# V3s register map
Vendor: Allwinner; Series: V3s; File version: 0.1
CPU: ARM Cortex-A7 MP1 0, little endian, MPU, no FPU, 0 interrupt priority bits
Registers are 32-bit, read-write, reset 0x0 unless marked. A register's access mark holds for its fields unless they carry their own. Offsets are from the block's base; [hi:lo] are bit positions; {n}, {i} and the like mark numbered series; 'fields as' and 'values as' point back to an identical list.

## PIO
Base 0x01C20800
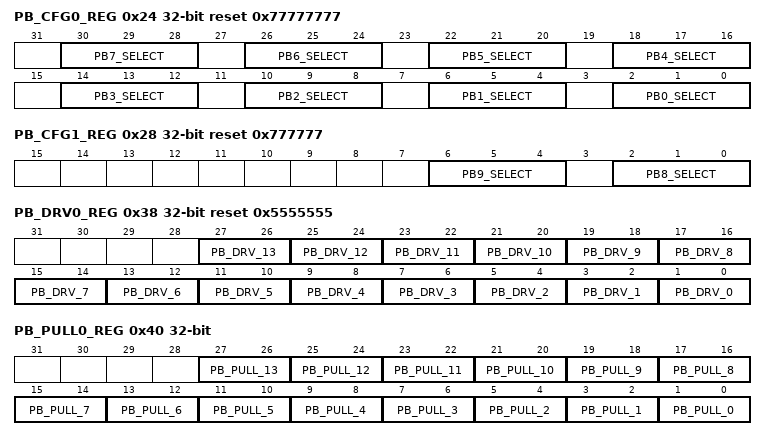
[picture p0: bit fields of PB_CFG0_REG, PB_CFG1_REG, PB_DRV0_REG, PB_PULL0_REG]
0x24 PB_CFG0_REG reset 0x77777777
  [30:28] PB7_SELECT — 000: Input 001: Output 010: TWI0_SDA 011: Reserved 100: Reserved 101: Reserved 110: PB_EINT7 111: IO Disable
    0=Input; 1=Output; 2=TWI0_SDA; 6=PB_EINT7; 7=IO (IO Disable)
  [26:24] PB6_SELECT — 000: Input 001: Output 010: TWI0_SCK 011: Reserved 100: Reserved 101: Reserved 110: PB_EINT6 111: IO Disable
    0=Input; 1=Output; 2=TWI0_SCK; 6=PB_EINT6; 7=IO (IO Disable)
  [22:20] PB5_SELECT — 000: Input 001: Output 010: PWM1 011: Reserved 100: Reserved 101: Reserved 110: PB_EINT5 111: IO Disable
    0=Input; 1=Output; 2=PWM1; 6=PB_EINT5; 7=IO (IO Disable)
  [18:16] PB4_SELECT — 000: Input 001: Output 010: PWM0 011: Reserved 100: Reserved 101: Reserved 110: PB_EINT4 111: IO Disable
    0=Input; 1=Output; 2=PWM0; 6=PB_EINT4; 7=IO (IO Disable)
  [14:12] PB3_SELECT — 000: Input 001: Output 010: UART2_CTS 011: Reserved 100: Reserved 101: Reserved 110: PB_EINT3 111: IO Disable
    0=Input; 1=Output; 2=UART2_CTS; 6=PB_EINT3; 7=IO (IO Disable)
  [10:8] PB2_SELECT — 000: Input 001: Output 010: UART2_RTS 011: Reserved 100: Reserved 101: Reserved 110: PB_EINT2 111: IO Disable
    0=Input; 1=Output; 2=UART2_RTS; 6=PB_EINT2; 7=IO (IO Disable)
  [6:4] PB1_SELECT — 000: Input 001: Output 010: UART2_RX 011: Reserved 100: Reserved 101: Reserved 110: PB_EINT1 111: IO Disable
    0=Input; 1=Output; 2=UART2_RX; 6=PB_EINT1; 7=IO (IO Disable)
  [2:0] PB0_SELECT — 000: Input 001: Output 010: UART2_TX 011: Reserved 100: Reserved 101: Reserved 110: PB_EINT0 111: IO Disable
    0=Input; 1=Output; 2=UART2_TX; 6=PB_EINT0; 7=IO (IO Disable)
0x28 PB_CFG1_REG reset 0x777777
  [6:4] PB9_SELECT — 000: Input 001: Output 010: TWI1_SDA 011: UART0_RX 100: Reserved 101: Reserved 110: PB_EINT9 111: IO Disable
    0=Input; 1=Output; 2=TWI1_SDA; 3=UART0_RX; 6=PB_EINT9; 7=IO (IO Disable)
  [2:0] PB8_SELECT — 000: Input 001: Output 010: TWI1_SCK 011: UART0_TX 100: Reserved 101: Reserved 110: PB_EINT8 111: IO Disable
    0=Input; 1=Output; 2=TWI1_SCK; 3=UART0_TX; 6=PB_EINT8; 7=IO (IO Disable)
0x2C PB_CFG2_REG reset not defined
0x30 PB_CFG3_REG reset not defined
0x34 PB_DATA_REG
  [13:0] PB_DAT — If the port is configured as input, the corresponding bit is the pin state. If the port is configured as output, the pin state is the same as the corresponding bit. The read bit value is the value setup by software. If the port is configured as functional pin, the undefined value will be read.
0x38 PB_DRV0_REG reset 0x5555555
  [2n+1:2n] PB_DRV_{n} (n=0..13) — PB[n] Multi-Driving Select (n = 0~13) 00: Level 0 01: Level 1 10: Level 2 11: Level 3
0x3C PB_DRV1_REG reset not defined
0x40 PB_PULL0_REG
  [2n+1:2n] PB_PULL_{n} (n=0..13) — PB[n] Pull-up/down Select (n = 0~13)00: Pull-up/down disable01: Pull-up 10: Pull-down 11: Reserved
0x44 PB_PULL1_REG reset not defined
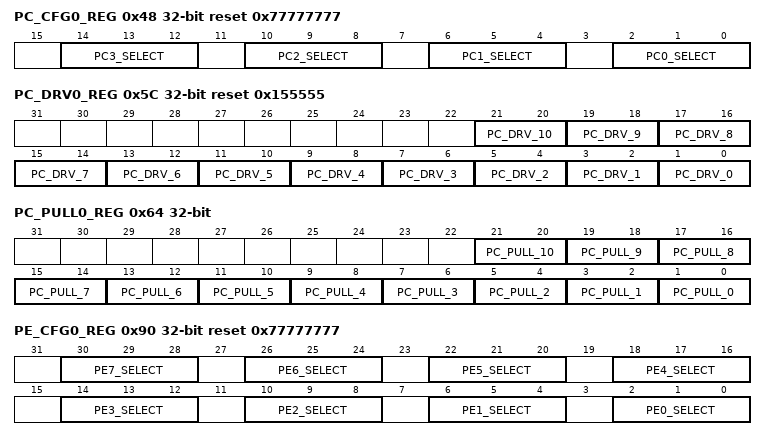
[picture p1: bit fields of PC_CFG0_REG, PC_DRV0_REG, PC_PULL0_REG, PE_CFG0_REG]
0x48 PC_CFG0_REG reset 0x77777777
  [14:12] PC3_SELECT — 000: Input 001: Output 010: SDC2_D0 011: SPI0_MOSI 100: Reserved 101: Reserved 110: Reserved 111: IO Disable
    0=Input; 1=Output; 2=SDC2_D0; 3=SPI0_MOSI; 7=IO (IO Disable)
  [10:8] PC2_SELECT — 000: Input 001: Output 010: SDC2_RST 011: SPI0_CS 100: Reserved 101: Reserved 110: Reserved 111: IO Disable
    0=Input; 1=Output; 2=SDC2_RST; 3=SPI0_CS; 7=IO (IO Disable)
  [6:4] PC1_SELECT — 000: Input 001: Output 010: SDC2_CMD 011: SPI0_CLK 100: Reserved 101: Reserved 110: Reserved 111: IO Disable
    0=Input; 1=Output; 2=SDC2_CMD; 3=SPI0_CLK; 7=IO (IO Disable)
  [2:0] PC0_SELECT — 000: Input 001: Output 010: SDC2_CLK 011: SPI0_MISO 100: Reserved 101: Reserved 110: Reserved 111: IO Disable
    0=Input; 1=Output; 2=SDC2_CLK; 3=SPI0_MISO; 7=IO (IO Disable)
0x4C PC_CFG1_REG reset 0x777 (reset mask 0x777)
0x50 PC_CFG2_REG reset not defined
0x54 PC_CFG3_REG reset not defined
0x58 PC_DATA_REG
  [10:0] PC_DAT — If the port is configured as input, the corresponding bit is the pin state. If the port is configured as output, the pin state is the same as the corresponding bit. The read bit value is the value setup by software. If the port is configured as functional pin, the undefined value will be read.
0x5C PC_DRV0_REG reset 0x155555
  [2n+1:2n] PC_DRV_{n} (n=0..10) — PC[n] Multi-Driving SELECT (n = 0~10) 00: Level 0 01: Level 1 10: Level 2 11: Level 3
0x60 PC_DRV1_REG reset not defined
0x64 PC_PULL0_REG
  [2n+1:2n] PC_PULL_{n} (n=0..10) — PC[n] Pull-up/down Select (n = 0~10) 00: Pull-up/down disable 01: Pull-up 10: Pull-down 11: Reserved
0x68 PC_PULL1_REG reset not defined
0x90 PE_CFG0_REG reset 0x77777777
  [4n+2:4n] PE{n}_SELECT (n=4..7) — 000: Input 001: Output 010: CSI_D{n-4} 011: LCD_D{n-2} 100: Reserved 101: Reserved 110: Reserved 111: IO Disable
    0=Input; 1=Output; 2=CSI_D{n-4}; 3=LCD_D{n-2}; 7=IO (IO Disable)
  [14:12] PE3_SELECT — 000: Input 001: Output 010: CSI_VSYNC 011: LCD_VSYNC 100: Reserved 101: Reserved 110: Reserved 111: IO Disable
    0=Input; 1=Output; 2=CSI_VSYNC; 3=LCD_VSYNC; 7=IO (IO Disable)
  [10:8] PE2_SELECT — 000: Input 001: Output 010: CSI_HSYNC 011: LCD_HSYNC 100: Reserved 101: Reserved 110: Reserved 111: IO Disable
    0=Input; 1=Output; 2=CSI_HSYNC; 3=LCD_HSYNC; 7=IO (IO Disable)
  [6:4] PE1_SELECT — 000: Input 001: Output 010: CSI_MCLK 011: LCD_DE 100: Reserved 101: Reserved 110: Reserved 111: IO Disable
    0=Input; 1=Output; 2=CSI_MCLK; 3=LCD_DE; 7=IO (IO Disable)
  [2:0] PE0_SELECT — 000: Input 001: Output 010: CSI_PCLK 011: LCD_CLK 100: Reserved 101: Reserved 110: Reserved 111: IO Disable
    0=Input; 1=Output; 2=CSI_PCLK; 3=LCD_CLK; 7=IO (IO Disable)
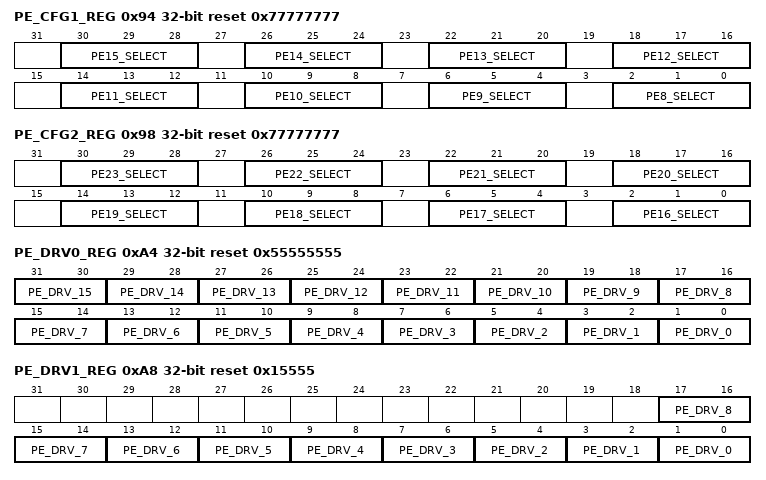
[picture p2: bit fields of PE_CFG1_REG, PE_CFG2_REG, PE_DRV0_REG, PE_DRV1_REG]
0x94 PE_CFG1_REG reset 0x77777777
  [4n-30:4n-32] PE{n}_SELECT (n=10..15) — 000: Input 001: Output 010: CSI_D{n-4} 011: LCD_D{n} 100: Reserved 101: Reserved 110: Reserved 111: IO Disable
    0=Input; 1=Output; 2=CSI_D{n-4}; 3=LCD_D{n}; 7=IO (IO Disable)
  [6:4] PE9_SELECT — 000: Input 001: Output 010: CSI_D5 011: LCD_D7 100: Reserved 101: Reserved 110: Reserved 111: IO Disable
    0=Input; 1=Output; 2=CSI_D5; 3=LCD_D7; 7=IO (IO Disable)
  [2:0] PE8_SELECT — 000: Input 001: Output 010: CSI_D4 011: LCD_D6 100: Reserved 101: Reserved 110: Reserved 111: IO Disable
    0=Input; 1=Output; 2=CSI_D4; 3=LCD_D6; 7=IO (IO Disable)
0x98 PE_CFG2_REG reset 0x77777777
  [30:28] PE23_SELECT — 000: Input 001: Output 010: Reserved 011: LCD_D22 100: UART1_RTS 101: Reserved 110: Reserved 111: IO Disable
    0=Input; 1=Output; 3=LCD_D22; 4=UART1_RTS; 7=IO (IO Disable)
  [26:24] PE22_SELECT — 000: Input 001: Output 010: CSI_SDA 011: TWI1_SDA 100: UART1_RX 101: Reserved 110: Reserved 111: IO Disable
    0=Input; 1=Output; 2=CSI_SDA; 3=TWI1_SDA; 4=UART1_RX; 7=IO (IO Disable)
  [22:20] PE21_SELECT — 000: Input 001: Output 010: CSI_SCK 011: TWI1_SCK 100: UART1_TX 101: Reserved 110: Reserved 111: IO Disable
    0=Input; 1=Output; 2=CSI_SCK; 3=TWI1_SCK; 4=UART1_TX; 7=IO (IO Disable)
  [18:16] PE20_SELECT — 000: Input 001: Output 010: CSI_FIELD 011: CSI_MIPI_MCLK 100: Reserved 101: Reserved 110: Reserved 111: IO Disable
    0=Input; 1=Output; 2=CSI_FIELD; 3=CSI_MIPI_MCLK; 7=IO (IO Disable)
  [4n-62:4n-64] PE{n}_SELECT (n=16..19) — 000: Input 001: Output 010: CSI_D{n-4} 011: LCD_D{n+2} 100: Reserved 101: Reserved 110: Reserved 111: IO Disable
    0=Input; 1=Output; 2=CSI_D{n-4}; 3=LCD_D{n+2}; 7=IO (IO Disable)
0x9C PE_CFG3_REG reset 0x7
  [2:0] PE24_SELECT — 000: Input 001: Output 010: Reserved 011: LCD_D23 100: UART1_CTS 101: Reserved 110: Reserved 111: IO Disable
    0=Input; 1=Output; 3=LCD_D23; 4=UART1_CTS; 7=IO (IO Disable)
0xA0 PE_DATA_REG
  [24:0] PE_DAT — If the port is configured as input, the corresponding bit is the pin state. If the port is configured as output, the pin state is the same as the corresponding bit. The read bit value is the value setup by software. If the port is configured as functional pin, the undefined value will be read.
0xA4 PE_DRV0_REG reset 0x55555555
  [2n+1:2n] PE_DRV_{n} (n=0..15) — PE[n] Multi-Driving SELECT (n = 0~15) 00: Level 0 01: Level 1 10: Level 2 11: Level 3
0xA8 PE_DRV1_REG reset 0x15555
  [2n+1:2n] PE_DRV_{n} (n=0..8) — PE[n] Multi-Driving Select (n = 16~24) 00: Level 0 01: Level 1 10: Level 2 11: Level 3
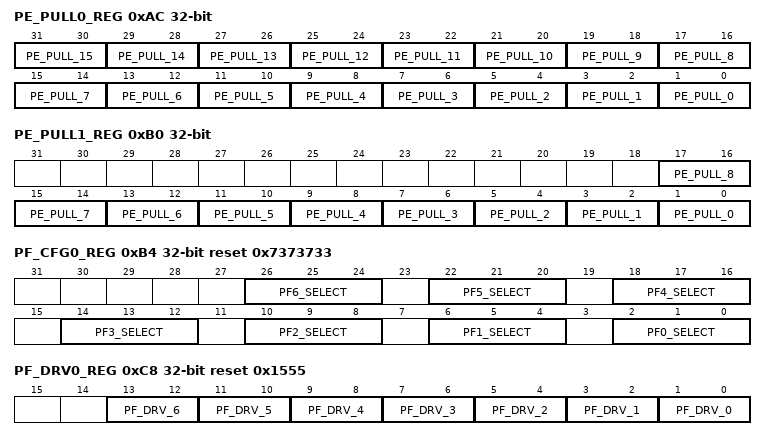
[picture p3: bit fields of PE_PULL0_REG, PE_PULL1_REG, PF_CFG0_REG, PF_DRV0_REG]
0xAC PE_PULL0_REG
  [2n+1:2n] PE_PULL_{n} (n=0..15) — PE[n] Pull-up/down Select (n = 0~15) 00: Pull-up/down disable 01: Pull-up 10: Pull-down 11: Reserved
0xB0 PE_PULL1_REG
  [2n+1:2n] PE_PULL_{n} (n=0..8) — PE[n] Pull-up/down Select (n = 16~24) 00: Pull-up/down disable 01: Pull-up 10: Pull-down 11: Reserved
0xB4 PF_CFG0_REG reset 0x7373733
  [26:24] PF6_SELECT — 000: Input 001: Output 010: Reserved 011: Reserved 100: Reserved 101: Reserved 110: Reserved 111: IO Disable
    0=Input; 1=Output; 7=IO (IO Disable)
  [22:20] PF5_SELECT — 000: Input 001: Output 010: SDC0_D2 011: JTAG_CK 100: Reserved 101: Reserved 110: Reserved 111: IO Disable
    0=Input; 1=Output; 2=SDC0_D2; 3=JTAG_CK; 7=IO (IO Disable)
  [18:16] PF4_SELECT — 000: Input 001: Output 010: SDC0_D3 011: UART0_RX 100: Reserved 101: Reserved 110: Reserved 111: IO Disable
    0=Input; 1=Output; 2=SDC0_D3; 3=UART0_RX; 7=IO (IO Disable)
  [14:12] PF3_SELECT — 000: Input 001: Output 010: SDC0_CMD 011: JTAG_DO 100: Reserved 101: Reserved 110: Reserved 111: IO Disable
    0=Input; 1=Output; 2=SDC0_CMD; 3=JTAG_DO; 7=IO (IO Disable)
  [10:8] PF2_SELECT — 000: Input 001: Output 010: SDC0_CLK 011: UART0_TX 100: Reserved 101: Reserved 110: Reserved 111: IO Disable
    0=Input; 1=Output; 2=SDC0_CLK; 3=UART0_TX; 7=IO (IO Disable)
  [6:4] PF1_SELECT — 000: Input 001: Output 010: SDC0_D0 011: JTAG_DI 100: Reserved 101: Reserved 110: Reserved 111: IO Disable
    0=Input; 1=Output; 2=SDC0_D0; 3=JTAG_DI; 7=IO (IO Disable)
  [2:0] PF0_SELECT — 000: Input 001: Output 010: SDC0_D1 011: JTAG_MS 100: Reserved 101: Reserved 110: Reserved 111: IO Disable
    0=Input; 1=Output; 2=SDC0_D1; 3=JTAG_MS; 7=IO (IO Disable)
{0xB4+4i} PF_CFG{i}_REG reset not defined (i=1..3)
0xC4 PF_DATA_REG
  [6:0] PF_DAT — If the port is configured as input, the corresponding bit is the pin state. If the port is configured as output, the pin state is the same as the corresponding bit. The read bit value is the value setup by software. If the port is configured as functional pin, the undefined value will be read.
0xC8 PF_DRV0_REG reset 0x1555
  [2n+1:2n] PF_DRV_{n} (n=0..6) — PF[n] Multi-Driving SELECT (n = 0~6)00: Level 0 01: Level 1 10: Level 2 11: Level 3
0xCC PF_DRV1_REG reset not defined
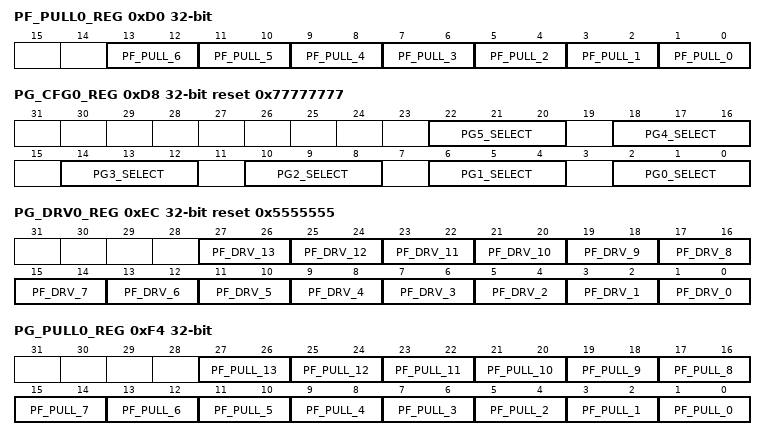
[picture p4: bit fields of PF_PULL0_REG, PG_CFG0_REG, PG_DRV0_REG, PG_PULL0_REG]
0xD0 PF_PULL0_REG
  [2n+1:2n] PF_PULL_{n} (n=0..6) — PF[n] Pull-up/down Select (n = 0~6) 00: Pull-up/down disable 01: Pull-up 10: Pull-down 11: Reserved
0xD4 PF_PULL1_REG reset not defined
0xD8 PG_CFG0_REG reset 0x77777777
  [4n+2:4n] PG{n}_SELECT (n=2..5) — 000: Input 001: Output 010: SDC1_D{n-2} 011: Reserved 100: Reserved 101: Reserved 110: PG_EINT{n} 111: IO Disable
    0=Input; 1=Output; 2=SDC1_D{n-2}; 6=PG_EINT{n}; 7=IO (IO Disable)
  [6:4] PG1_SELECT — 000: Input 001: Output 010: SDC1_CMD 011: Reserved 100: Reserved 101: Reserved 110: PG_EINT1 111: IO Disable
    0=Input; 1=Output; 2=SDC1_CMD; 6=PG_EINT1; 7=IO (IO Disable)
  [2:0] PG0_SELECT — 000: Input 001: Output 010: SDC1_CLK 011: Reserved 100: Reserved 101: Reserved 110: PG_EINT0 111: IO Disable
    0=Input; 1=Output; 2=SDC1_CLK; 6=PG_EINT0; 7=IO (IO Disable)
0xDC PG_CFG1_REG reset 0x777777
0xE0 PG_CFG2_REG reset not defined
0xE4 PG_CFG3_REG reset not defined
0xE8 PG_DATA_REG
  [13:0] PG_DAT — If the port is configured as input, the corresponding bit is the pin state. If the port is configured as output, the pin state is the same as the corresponding bit. The read bit value is the value setup by software. If the port is configured as functional pin, the undefined value will be read.
0xEC PG_DRV0_REG reset 0x5555555
  [2n+1:2n] PF_DRV_{n} (n=0..13) — PF[n] Multi-Driving SELECT (n = 0~13) 00: Level 0 01: Level 1 10: Level 2 11: Level 3
0xF0 PG_DRV1_REG reset not defined
0xF4 PG_PULL0_REG
  [2n+1:2n] PF_PULL_{n} (n=0..13) — PF[n] Pull-up/down Select (n = 0~13) 00: Pull-up/down disable 01: Pull-up 10: Pull-down 11: Reserved
0xF8 PG_PULL1_REG reset not defined
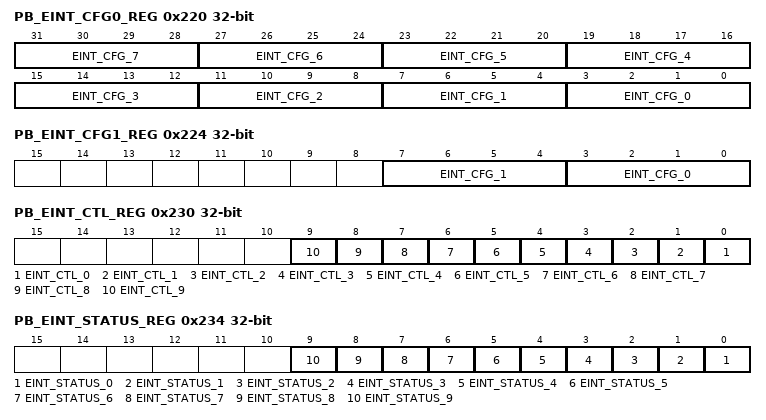
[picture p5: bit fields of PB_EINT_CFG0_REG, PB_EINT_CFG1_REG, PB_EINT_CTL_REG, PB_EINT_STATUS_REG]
0x220 PB_EINT_CFG0_REG
  [4n+3:4n] EINT_CFG_{n} (n=0..7) — External INTn Mode (n = 0~7) 0x0: Positive Edge 0x1: Negative Edge 0x2: High Level 0x3: Low Level 0x4: Double Edge (Positive/ Negative) Others: Reserved
0x224 PB_EINT_CFG1_REG
  [7:4] EINT_CFG_1 — External INTn Mode (n = 8~9) 0x0: Positive Edge 0x1: Negative Edge 0x2: High Level 0x3: Low Level 0x4: Double Edge (Positive/ Negative) Others: Reserved
  [3:0] EINT_CFG_0 — External INTn Mode (n = 8~9) 0x0: Positive Edge 0x1: Negative Edge 0x2: High Level 0x3: Low Level 0x4: Double Edge (Positive/ Negative) Others: Reserved
0x228 PB_EINT_CFG2_REG reset not defined
0x22C PB_EINT_CFG3_REG reset not defined
0x230 PB_EINT_CTL_REG
  [n] EINT_CTL_{n} (n=0..9) — External INTn Enable (n = 0~9) 0: Disable 1: Enable
0x234 PB_EINT_STATUS_REG
  [n] EINT_STATUS_{n} (n=0..9) — External INTn Pending Bit (n = 0~9) 0: No IRQ pending 1: IRQ pending Write `1` to clear it.
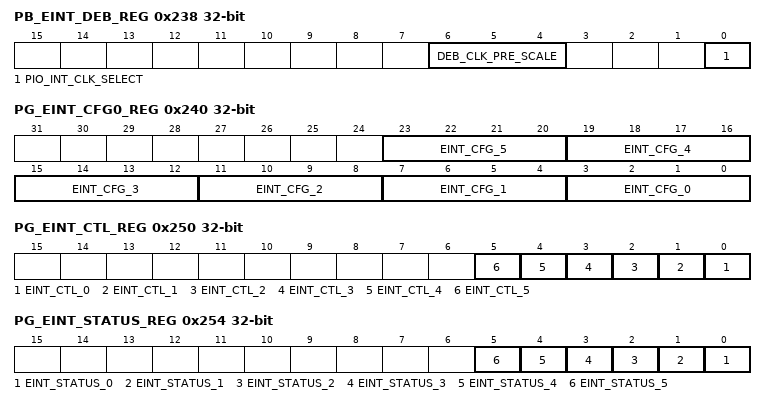
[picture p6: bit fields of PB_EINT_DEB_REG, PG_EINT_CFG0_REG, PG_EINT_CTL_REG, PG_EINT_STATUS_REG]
0x238 PB_EINT_DEB_REG
  [6:4] DEB_CLK_PRE_SCALE — Debounce Clock Pre-scale n The selected clock source is prescaled by 2^n.
  [0] PIO_INT_CLK_SELECT — PIO Interrupt Clock Select 0: LOSC 32Khz 1: HOSC 24Mhz
    0=LOSC (LOSC 32Khz); 1=HOSC (HOSC 24Mhz)
0x240 PG_EINT_CFG0_REG
  [4n+3:4n] EINT_CFG_{n} (n=0..5) — External INTn Mode (n = 0~5) 0x0: Positive Edge 0x1: Negative Edge 0x2: High Level 0x3: Low Level 0x4: Double Edge (Positive/ Negative) Others: Reserved
{0x240+4i} PG_EINT_CFG{i}_REG reset not defined (i=1..3)
0x250 PG_EINT_CTL_REG
  [n] EINT_CTL_{n} (n=0..5) — External INTn Enable (n = 0~5) 0: Disable 1: Enable
0x254 PG_EINT_STATUS_REG
  [n] EINT_STATUS_{n} (n=0..5) — External INTn Pending Bit (n = 0~5) 0: No IRQ pending 1: IRQ pending Write `1` to clear it.
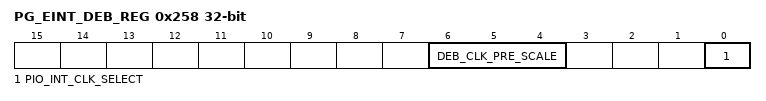
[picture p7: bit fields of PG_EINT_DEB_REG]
0x258 PG_EINT_DEB_REG
  fields as PB_EINT_DEB_REG
